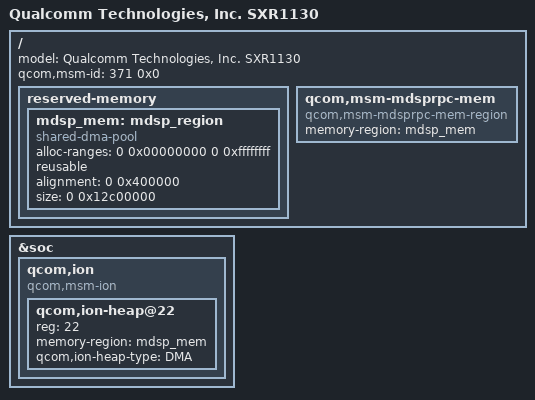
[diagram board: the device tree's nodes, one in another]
/*
 * Copyright (c) 2018, The Linux Foundation. All rights reserved.
 *
 * This program is free software; you can redistribute it and/or modify
 * it under the terms of the GNU General Public License version 2 and
 * only version 2 as published by the Free Software Foundation.
 *
 * This program is distributed in the hope that it will be useful,
 * but WITHOUT ANY WARRANTY; without even the implied warranty of
 * MERCHANTABILITY or FITNESS FOR A PARTICULAR PURPOSE.  See the
 * GNU General Public License for more details.
 */

#include "qcs605.dtsi"

/ {
	model = "Qualcomm Technologies, Inc. SXR1130";
	qcom,msm-id = <371 0x0>;

	reserved-memory {
		mdsp_mem: mdsp_region {
			compatible = "shared-dma-pool";
			alloc-ranges = <0 0x00000000 0 0xffffffff>;
			reusable;
			alignment = <0 0x400000>;
			size = <0 0x12c00000>;
		};
	};

	qcom,msm-mdsprpc-mem {
		compatible = "qcom,msm-mdsprpc-mem-region";
		memory-region = <&mdsp_mem>;
	};
};

&soc {
	qcom,ion {
		compatible = "qcom,msm-ion";

		qcom,ion-heap@22 { /* MDSP HEAP */
			reg = <22>;
			memory-region = <&mdsp_mem>;
			qcom,ion-heap-type = "DMA";
		};
	};
};
